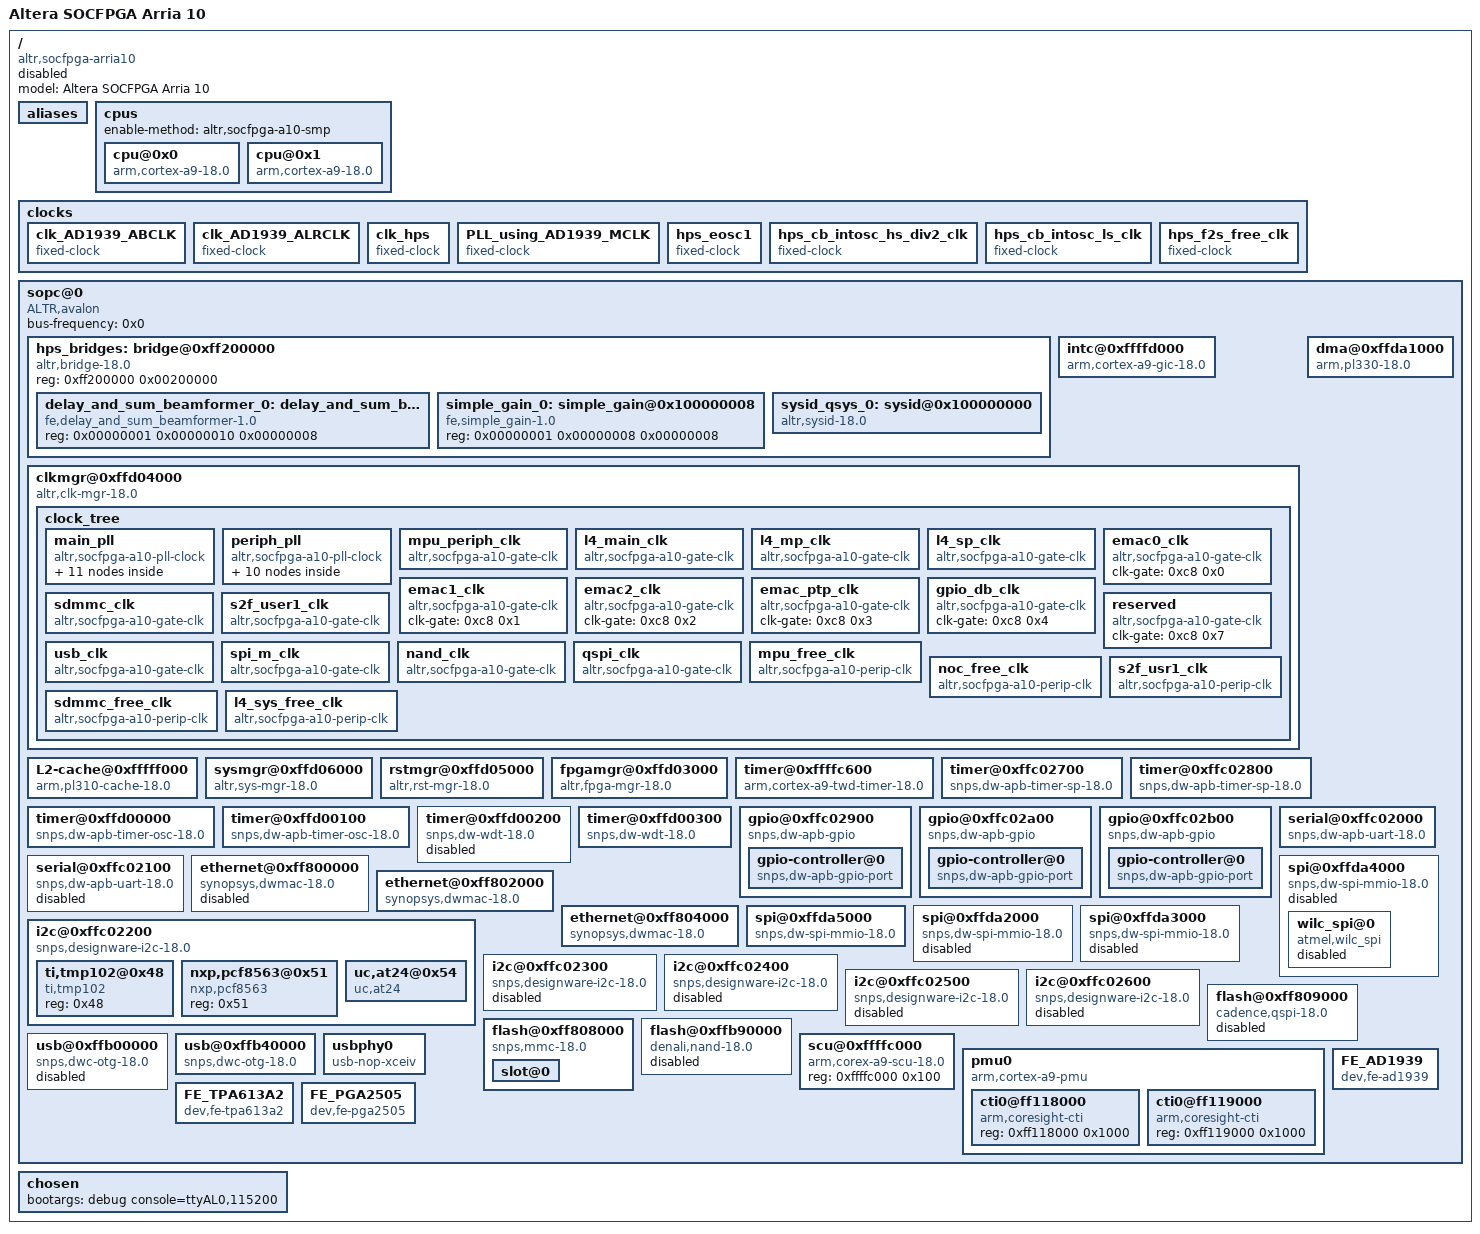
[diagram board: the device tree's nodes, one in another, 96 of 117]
/dts-v1/;

/ {
	model = "Altera SOCFPGA Arria 10";
	compatible = "altr,socfpga-arria10", "altr,socfpga";
	#address-cells = <0x1>;
	#size-cells = <0x1>;
	status = "disabled";

	aliases {
		ethernet0 = "/sopc@0/ethernet@0xff800000";
		ethernet1 = "/sopc@0/ethernet@0xff802000";
		ethernet2 = "/sopc@0/ethernet@0xff804000";
		serial0 = "/sopc@0/serial@0xffc02100";
	};

	cpus {
		#address-cells = <0x1>;
		#size-cells = <0x0>;
		enable-method = "altr,socfpga-a10-smp";

		cpu@0x0 {
			device_type = "cpu";
			compatible = "arm,cortex-a9-18.0", "arm,cortex-a9";
			reg = <0x0>;
			next-level-cache = <0x1>;
		};

		cpu@0x1 {
			device_type = "cpu";
			compatible = "arm,cortex-a9-18.0", "arm,cortex-a9";
			reg = <0x1>;
			next-level-cache = <0x1>;
		};
	};

	clocks {
		#address-cells = <0x1>;
		#size-cells = <0x1>;

		clk_AD1939_ABCLK {
			compatible = "fixed-clock";
			#clock-cells = <0x0>;
			clock-frequency = <0x2faf080>;
			clock-output-names = "clk_AD1939_ABCLK-clk";
		};

		clk_AD1939_ALRCLK {
			compatible = "fixed-clock";
			#clock-cells = <0x0>;
			clock-frequency = <0x2faf080>;
			clock-output-names = "clk_AD1939_ALRCLK-clk";
		};

		clk_hps {
			compatible = "fixed-clock";
			#clock-cells = <0x0>;
			clock-frequency = <0x17d7840>;
			clock-output-names = "clk_hps-clk";
			linux,phandle = <0x2>;
			phandle = <0x2>;
		};

		PLL_using_AD1939_MCLK {
			compatible = "fixed-clock";
			#clock-cells = <0x0>;
			clock-frequency = <0x5dc0000>;
			clock-output-names = "PLL_using_AD1939_MCLK-outclk0";
		};

		hps_eosc1 {
			compatible = "fixed-clock";
			#clock-cells = <0x0>;
			clock-frequency = <0x17d7840>;
			clock-output-names = "hps_eosc1-clk";
			linux,phandle = <0x3>;
			phandle = <0x3>;
		};

		hps_cb_intosc_hs_div2_clk {
			compatible = "fixed-clock";
			#clock-cells = <0x0>;
			clock-frequency = <0x0>;
			clock-output-names = "hps_cb_intosc_hs_div2_clk-clk";
			linux,phandle = <0x4>;
			phandle = <0x4>;
		};

		hps_cb_intosc_ls_clk {
			compatible = "fixed-clock";
			#clock-cells = <0x0>;
			clock-frequency = <0x3938700>;
			clock-output-names = "hps_cb_intosc_ls_clk-clk";
			linux,phandle = <0x5>;
			phandle = <0x5>;
		};

		hps_f2s_free_clk {
			compatible = "fixed-clock";
			#clock-cells = <0x0>;
			clock-frequency = <0xbebc200>;
			clock-output-names = "hps_f2s_free_clk-clk";
			linux,phandle = <0x6>;
			phandle = <0x6>;
		};
	};

	sopc@0 {
		device_type = "soc";
		ranges;
		#address-cells = <0x1>;
		#size-cells = <0x1>;
		compatible = "ALTR,avalon", "simple-bus";
		bus-frequency = <0x0>;

        hps_bridges: bridge@0xff200000 {
                compatible = "altr,bridge-18.0", "simple-bus";
                reg = <0xff200000 0x00200000>;
                #address-cells = <2>;
                #size-cells = <1>;
                ranges = <0x00000001 0x00000010 0xff200010 0x00000008>,
                        <0x00000001 0x00000008 0xff200008 0x00000008>,
                        <0x00000001 0x00000000 0xff200000 0x00000008>;

                delay_and_sum_beamformer_0: delay_and_sum_beamformer@0x100000010 {
                        compatible = "fe,delay_and_sum_beamformer-1.0", "dev,fe-delay_and_sum_beamformer";
                        reg = <0x00000001 0x00000010 0x00000008>;
                }; //end delay_and_sum_beamformer@0x100000010 (delay_and_su m_beamformer_0)

                simple_gain_0: simple_gain@0x100000008 {
                        compatible = "fe,simple_gain-1.0", "dev,fe-simple_gain";
                        reg = <0x00000001 0x00000008 0x00000008>;
                }; //end simple_gain@0x100000008 (simple_gain_0)

                sysid_qsys_0: sysid@0x100000000 {
                        compatible = "altr,sysid-18.0", "altr,sysid-1.0";
                        reg = <0x00000001 0x00000000 0x00000008>;
                        id = <1>;       /* embeddedsw.dts.params.id type NU MBER */
                        timestamp = <1585258689>;       /* embeddedsw.dts.p arams.timestamp type NUMBER */
                }; //end sysid@0x100000000 (sysid_qsys_0)
        }; //end bridge@0xff200000 (hps_bridges)


		intc@0xffffd000 {
			compatible = "arm,cortex-a9-gic-18.0", "arm,cortex-a9-gic";
			reg = <0xffffd000 0x1000 0xffffc100 0x100>;
			reg-names = "axi_slave0", "axi_slave1";
			interrupt-controller;
			#interrupt-cells = <0x3>;
			linux,phandle = <0x17>;
			phandle = <0x17>;
		};

		clkmgr@0xffd04000 {
			compatible = "altr,clk-mgr-18.0", "altr,clk-mgr";
			reg = <0xffd04000 0x1000>;
			clocks = <0x3 0x4 0x5 0x6>;
			clock-names = "eosc1", "cb_intosc_hs_div2_clk", "cb_intosc_ls_clk", "f2s_free_clk";

			clock_tree {
				#size-cells = <0x0>;
				#address-cells = <0x1>;

				main_pll {
					compatible = "altr,socfpga-a10-pll-clock";
					reg = <0x40>;
					clocks = <0x3 0x5 0x6>;
					clock-names = "hps_eosc1", "hps_cb_intosc_ls_clk", "hps_f2s_free_clk";
					#clock-cells = <0x0>;
					#address-cells = <0x1>;
					#size-cells = <0x0>;
					linux,phandle = <0x7>;
					phandle = <0x7>;

					main_mpu_base_clk {
						compatible = "altr,socfpga-a10-perip-clk";
						reg = <0x40>;
						clocks = <0x7>;
						#clock-cells = <0x0>;
						div-reg = <0x140 0x0 0xb>;
						linux,phandle = <0x10>;
						phandle = <0x10>;
					};

					main_noc_base_clk {
						compatible = "altr,socfpga-a10-perip-clk";
						reg = <0x40>;
						clocks = <0x7>;
						#clock-cells = <0x0>;
						div-reg = <0x144 0x0 0xb>;
						linux,phandle = <0x12>;
						phandle = <0x12>;
					};

					main_emaca_clk {
						compatible = "altr,socfpga-a10-perip-clk";
						reg = <0x68>;
						clocks = <0x7>;
						#clock-cells = <0x0>;
					};

					main_emacb_clk {
						compatible = "altr,socfpga-a10-perip-clk";
						reg = <0x6c>;
						clocks = <0x7>;
						#clock-cells = <0x0>;
					};

					main_emac_ptp_clk {
						compatible = "altr,socfpga-a10-perip-clk";
						reg = <0x70>;
						clocks = <0x7>;
						#clock-cells = <0x0>;
					};

					main_gpio_db_clk {
						compatible = "altr,socfpga-a10-perip-clk";
						reg = <0x74>;
						clocks = <0x7>;
						#clock-cells = <0x0>;
					};

					main_sdmmc_clk {
						compatible = "altr,socfpga-a10-perip-clk";
						reg = <0x78>;
						clocks = <0x7>;
						#clock-cells = <0x0>;
						linux,phandle = <0x15>;
						phandle = <0x15>;
					};

					main_s2f_usr0_clk {
						compatible = "altr,socfpga-a10-perip-clk";
						reg = <0x7c>;
						clocks = <0x7>;
						#clock-cells = <0x0>;
					};

					main_s2f_usr1_clk {
						compatible = "altr,socfpga-a10-perip-clk";
						reg = <0x80>;
						clocks = <0x7>;
						#clock-cells = <0x0>;
						linux,phandle = <0x14>;
						phandle = <0x14>;
					};

					main_hmc_pll_ref_clk {
						compatible = "altr,socfpga-a10-perip-clk";
						reg = <0x84>;
						clocks = <0x7>;
						#clock-cells = <0x0>;
					};

					main_periph_ref_clk {
						compatible = "altr,socfpga-a10-perip-clk";
						reg = <0x9c>;
						clocks = <0x7>;
						#clock-cells = <0x0>;
						linux,phandle = <0x8>;
						phandle = <0x8>;
					};
				};

				periph_pll {
					compatible = "altr,socfpga-a10-pll-clock";
					reg = <0xc0>;
					clocks = <0x3 0x5 0x6 0x8>;
					clock-names = "hps_eosc1", "hps_cb_intosc_ls_clk", "hps_f2s_free_clk", "main_periph_ref_clk";
					#clock-cells = <0x0>;
					#address-cells = <0x1>;
					#size-cells = <0x0>;
					linux,phandle = <0x9>;
					phandle = <0x9>;

					peri_mpu_base_clk {
						compatible = "altr,socfpga-a10-perip-clk";
						reg = <0xc0>;
						clocks = <0x9>;
						#clock-cells = <0x0>;
						div-reg = <0x140 0x10 0xb>;
						linux,phandle = <0x11>;
						phandle = <0x11>;
					};

					peri_noc_base_clk {
						compatible = "altr,socfpga-a10-perip-clk";
						reg = <0xc0>;
						clocks = <0x9>;
						#clock-cells = <0x0>;
						div-reg = <0x144 0x10 0xb>;
						linux,phandle = <0x13>;
						phandle = <0x13>;
					};

					peri_emaca_clk {
						compatible = "altr,socfpga-a10-perip-clk";
						reg = <0xe8>;
						clocks = <0x9>;
						#clock-cells = <0x0>;
					};

					peri_emacb_clk {
						compatible = "altr,socfpga-a10-perip-clk";
						reg = <0xec>;
						clocks = <0x9>;
						#clock-cells = <0x0>;
					};

					peri_emac_ptp_clk {
						compatible = "altr,socfpga-a10-perip-clk";
						reg = <0xf0>;
						clocks = <0x9>;
						#clock-cells = <0x0>;
					};

					peri_gpio_db_clk {
						compatible = "altr,socfpga-a10-perip-clk";
						reg = <0xf4>;
						clocks = <0x9>;
						#clock-cells = <0x0>;
					};

					peri_sdmmc_clk {
						compatible = "altr,socfpga-a10-perip-clk";
						reg = <0xf8>;
						clocks = <0x9>;
						#clock-cells = <0x0>;
						linux,phandle = <0x16>;
						phandle = <0x16>;
					};

					peri_s2f_usr0_clk {
						compatible = "altr,socfpga-a10-perip-clk";
						reg = <0xfc>;
						clocks = <0x9>;
						#clock-cells = <0x0>;
					};

					peri_s2f_usr1_clk {
						compatible = "altr,socfpga-a10-perip-clk";
						reg = <0x100>;
						clocks = <0x9>;
						#clock-cells = <0x0>;
						linux,phandle = <0xd>;
						phandle = <0xd>;
					};

					peri_hmc_pll_ref_clk {
						compatible = "altr,socfpga-a10-perip-clk";
						reg = <0x104>;
						clocks = <0x9>;
						#clock-cells = <0x0>;
					};
				};

				mpu_periph_clk {
					compatible = "altr,socfpga-a10-gate-clk";
					clocks = <0xa>;
					#clock-cells = <0x0>;
					clk-gate = <0x48 0x0>;
					fixed-divider = <0x4>;
					linux,phandle = <0x18>;
					phandle = <0x18>;
				};

				l4_main_clk {
					compatible = "altr,socfpga-a10-gate-clk";
					clocks = <0xb>;
					#clock-cells = <0x0>;
					clk-gate = <0x48 0x1>;
					div-reg = <0xa8 0x0 0x2>;
					linux,phandle = <0xf>;
					phandle = <0xf>;
				};

				l4_mp_clk {
					compatible = "altr,socfpga-a10-gate-clk";
					clocks = <0xb>;
					#clock-cells = <0x0>;
					clk-gate = <0x48 0x2>;
					div-reg = <0xa8 0x8 0x2>;
					linux,phandle = <0xe>;
					phandle = <0xe>;
				};

				l4_sp_clk {
					compatible = "altr,socfpga-a10-gate-clk";
					clocks = <0xb>;
					#clock-cells = <0x0>;
					clk-gate = <0x48 0x3>;
					div-reg = <0xa8 0x10 0x2>;
					linux,phandle = <0x19>;
					phandle = <0x19>;
				};

				emac0_clk {
					compatible = "altr,socfpga-a10-gate-clk";
					#clock-cells = <0x0>;
					clk-gate = <0xc8 0x0>;
				};

				emac1_clk {
					compatible = "altr,socfpga-a10-gate-clk";
					#clock-cells = <0x0>;
					clk-gate = <0xc8 0x1>;
				};

				emac2_clk {
					compatible = "altr,socfpga-a10-gate-clk";
					#clock-cells = <0x0>;
					clk-gate = <0xc8 0x2>;
				};

				emac_ptp_clk {
					compatible = "altr,socfpga-a10-gate-clk";
					#clock-cells = <0x0>;
					clk-gate = <0xc8 0x3>;
				};

				gpio_db_clk {
					compatible = "altr,socfpga-a10-gate-clk";
					#clock-cells = <0x0>;
					clk-gate = <0xc8 0x4>;
				};

				sdmmc_clk {
					compatible = "altr,socfpga-a10-gate-clk";
					clocks = <0xc>;
					#clock-cells = <0x0>;
					clk-gate = <0xc8 0x5>;
					clk-phase = <0x0 0x87>;
					linux,phandle = <0x1f>;
					phandle = <0x1f>;
				};

				s2f_user1_clk {
					compatible = "altr,socfpga-a10-gate-clk";
					clocks = <0xd>;
					#clock-cells = <0x0>;
					clk-gate = <0xc8 0x6>;
				};

				reserved {
					compatible = "altr,socfpga-a10-gate-clk";
					#clock-cells = <0x0>;
					clk-gate = <0xc8 0x7>;
				};

				usb_clk {
					compatible = "altr,socfpga-a10-gate-clk";
					clocks = <0xe>;
					#clock-cells = <0x0>;
					clk-gate = <0xc8 0x8>;
					linux,phandle = <0x20>;
					phandle = <0x20>;
				};

				spi_m_clk {
					compatible = "altr,socfpga-a10-gate-clk";
					clocks = <0xf>;
					#clock-cells = <0x0>;
					clk-gate = <0xc8 0x9>;
					linux,phandle = <0x1d>;
					phandle = <0x1d>;
				};

				nand_clk {
					compatible = "altr,socfpga-a10-gate-clk";
					clocks = <0xe>;
					#clock-cells = <0x0>;
					clk-gate = <0xc8 0xa>;
				};

				qspi_clk {
					compatible = "altr,socfpga-a10-gate-clk";
					clocks = <0xf>;
					#clock-cells = <0x0>;
					clk-gate = <0xc8 0xb>;
					linux,phandle = <0x1e>;
					phandle = <0x1e>;
				};

				mpu_free_clk {
					compatible = "altr,socfpga-a10-perip-clk";
					clocks = <0x10 0x11 0x3 0x4 0x6>;
					clock-names = "main_mpu_base_clk", "peri_mpu_base_clk", "hps_eosc1", "hps_cb_intosc_hs_div2_clk", "hps_f2s_free_clk";
					#clock-cells = <0x0>;
					reg = <0x60>;
					linux,phandle = <0xa>;
					phandle = <0xa>;
				};

				noc_free_clk {
					compatible = "altr,socfpga-a10-perip-clk";
					clocks = <0x12 0x13 0x3 0x4 0x6>;
					clock-names = "main_noc_base_clk", "peri_noc_base_clk", "hps_eosc1", "hps_cb_intosc_hs_div2_clk", "hps_f2s_free_clk";
					#clock-cells = <0x0>;
					reg = <0x64>;
					linux,phandle = <0xb>;
					phandle = <0xb>;
				};

				s2f_usr1_clk {
					compatible = "altr,socfpga-a10-perip-clk";
					clocks = <0x14 0xd 0x3 0x4 0x6>;
					clock-names = "main_s2f_usr1_clk", "peri_s2f_usr1_clk", "hps_eosc1", "hps_cb_intosc_hs_div2_clk", "hps_f2s_free_clk";
					#clock-cells = <0x0>;
					reg = <0x104>;
				};

				sdmmc_free_clk {
					compatible = "altr,socfpga-a10-perip-clk";
					clocks = <0x15 0x16 0x3 0x4 0x6>;
					clock-names = "main_sdmmc_clk", "peri_sdmmc_clk", "hps_eosc1", "hps_cb_intosc_hs_div2_clk", "hps_f2s_free_clk";
					#clock-cells = <0x0>;
					reg = <0xf8>;
					fixed-divider = <0x4>;
					linux,phandle = <0xc>;
					phandle = <0xc>;
				};

				l4_sys_free_clk {
					compatible = "altr,socfpga-a10-perip-clk";
					clocks = <0xb>;
					#clock-cells = <0x0>;
					fixed-divider = <0x4>;
					linux,phandle = <0x1a>;
					phandle = <0x1a>;
				};
			};
		};

		L2-cache@0xfffff000 {
			compatible = "arm,pl310-cache-18.0", "arm,pl310-cache";
			reg = <0xfffff000 0x1000>;
			interrupt-parent = <0x17>;
			interrupts = <0x0 0x12 0x4>;
			cache-level = <0x2>;
			cache-unified;
			arm,tag-latency = <0x1 0x1 0x1>;
			arm,data-latency = <0x2 0x1 0x1>;
			linux,phandle = <0x1>;
			phandle = <0x1>;
		};

		dma@0xffda1000 {
			compatible = "arm,pl330-18.0", "arm,pl330", "arm,primecell";
			reg = <0xffda1000 0x1000>;
			interrupt-parent = <0x17>;
			interrupts = <0x0 0x53 0x4>;
			clocks = <0xf>;
			#dma-cells = <0x1>;
			#dma-channels = <0x8>;
			#dma-requests = <0x20>;
			clock-names = "apb_pclk";
			copy-align = <0x3>;
			nr-irqs = <0x9>;
			nr-valid-peri = <0x9>;
		};

		sysmgr@0xffd06000 {
			compatible = "altr,sys-mgr-18.0", "altr,sys-mgr", "syscon";
			reg = <0xffd06000 0x400>;
			cpu1-start-addr = <0xffd06230>;
			linux,phandle = <0x1c>;
			phandle = <0x1c>;
		};

		rstmgr@0xffd05000 {
			compatible = "altr,rst-mgr-18.0", "altr,rst-mgr", "syscon";
			reg = <0xffd05000 0x100>;
			#reset-cells = <0x1>;
			altr,modrst-offset = <0x20>;
			linux,phandle = <0x1b>;
			phandle = <0x1b>;
		};

		fpgamgr@0xffd03000 {
			compatible = "altr,fpga-mgr-18.0", "altr,socfpga-a10-fpga-mgr";
			reg = <0xffd03000 0x1000 0xffcfe400 0x100>;
			reg-names = "axi_slave0", "axi_slave1";
			interrupt-parent = <0x17>;
			interrupts = <0x0 0x7b 0x4>;
			transport = "mmio";
			clocks = <0xe>;
		};

		timer@0xffffc600 {
			compatible = "arm,cortex-a9-twd-timer-18.0", "arm,cortex-a9-twd-timer";
			reg = <0xffffc600 0x100>;
			interrupt-parent = <0x17>;
			interrupts = <0x1 0xd 0xf04>;
			clocks = <0x18>;
		};

		timer@0xffc02700 {
			compatible = "snps,dw-apb-timer-sp-18.0", "snps,dw-apb-timer-sp";
			reg = <0xffc02700 0x100>;
			interrupt-parent = <0x17>;
			interrupts = <0x0 0x73 0x4>;
			clocks = <0x19>;
			clock-names = "timer";
		};

		timer@0xffc02800 {
			compatible = "snps,dw-apb-timer-sp-18.0", "snps,dw-apb-timer-sp";
			reg = <0xffc02800 0x100>;
			interrupt-parent = <0x17>;
			interrupts = <0x0 0x74 0x4>;
			clocks = <0x19>;
			clock-names = "timer";
		};

		timer@0xffd00000 {
			compatible = "snps,dw-apb-timer-osc-18.0", "snps,dw-apb-timer-osc";
			reg = <0xffd00000 0x100>;
			interrupt-parent = <0x17>;
			interrupts = <0x0 0x75 0x4>;
			clocks = <0x1a>;
			clock-names = "timer";
		};

		timer@0xffd00100 {
			compatible = "snps,dw-apb-timer-osc-18.0", "snps,dw-apb-timer-osc";
			reg = <0xffd00100 0x100>;
			interrupt-parent = <0x17>;
			interrupts = <0x0 0x76 0x4>;
			clocks = <0x1a>;
			clock-names = "timer";
		};

		timer@0xffd00200 {
			compatible = "snps,dw-wdt-18.0", "snps,dw-wdt";
			reg = <0xffd00200 0x100>;
			interrupt-parent = <0x17>;
			interrupts = <0x0 0x77 0x4>;
			clocks = <0x1a>;
			clock-names = "timer";
			status = "disabled";
		};

		timer@0xffd00300 {
			compatible = "snps,dw-wdt-18.0", "snps,dw-wdt";
			reg = <0xffd00300 0x100>;
			interrupt-parent = <0x17>;
			interrupts = <0x0 0x78 0x4>;
			clocks = <0x1a>;
			clock-names = "timer";
		};

		gpio@0xffc02900 {
			compatible = "snps,dw-apb-gpio", "snps,dw-gpio-18.0", "snps,dw-gpio";
			reg = <0xffc02900 0x100>;
			interrupt-parent = <0x17>;
			interrupts = <0x0 0x70 0x4>;
			clocks = <0xe>;
			#gpio-cells = <0x2>;
			gpio-controller;
			#address-cells = <0x1>;
			#size-cells = <0x0>;

			gpio-controller@0 {
				compatible = "snps,dw-apb-gpio-port";
				gpio-controller;
				#gpio-cells = <0x2>;
				snps,nr-gpios = <0x18>;
				reg = <0x0>;
				interrupt-controller;
				#interrupt-cells = <0x2>;
				interrupts = <0x0 0x70 0x4>;
				interrupt-parent = <0x17>;
			};
		};

		gpio@0xffc02a00 {
			compatible = "snps,dw-apb-gpio", "snps,dw-gpio-18.0", "snps,dw-gpio";
			reg = <0xffc02a00 0x100>;
			interrupt-parent = <0x17>;
			interrupts = <0x0 0x71 0x4>;
			clocks = <0xe>;
			#gpio-cells = <0x2>;
			gpio-controller;
			#address-cells = <0x1>;
			#size-cells = <0x0>;

			gpio-controller@0 {
				compatible = "snps,dw-apb-gpio-port";
				gpio-controller;
				#gpio-cells = <0x2>;
				snps,nr-gpios = <0x18>;
				reg = <0x0>;
				interrupt-controller;
				#interrupt-cells = <0x2>;
				interrupts = <0x0 0x71 0x4>;
				interrupt-parent = <0x17>;
			};
		};

		gpio@0xffc02b00 {
			compatible = "snps,dw-apb-gpio", "snps,dw-gpio-18.0", "snps,dw-gpio";
			reg = <0xffc02b00 0x100>;
			interrupt-parent = <0x17>;
			interrupts = <0x0 0x72 0x4>;
			clocks = <0xe>;
			#gpio-cells = <0x2>;
			gpio-controller;
			#address-cells = <0x1>;
			#size-cells = <0x0>;

			gpio-controller@0 {
				compatible = "snps,dw-apb-gpio-port";
				gpio-controller;
				#gpio-cells = <0x2>;
				snps,nr-gpios = <0xe>;
				reg = <0x0>;
				interrupt-controller;
				#interrupt-cells = <0x2>;
				interrupts = <0x0 0x72 0x4>;
				interrupt-parent = <0x17>;
			};
		};

		serial@0xffc02000 {
			compatible = "snps,dw-apb-uart-18.0", "snps,dw-apb-uart";
			reg = <0xffc02000 0x100>;
			interrupt-parent = <0x17>;
			interrupts = <0x0 0x6e 0x4>;
			clocks = <0x19>;
			reg-io-width = <0x4>;
			reg-shift = <0x2>;
			status = "okay";
		};

		serial@0xffc02100 {
			compatible = "snps,dw-apb-uart-18.0", "snps,dw-apb-uart";
			reg = <0xffc02100 0x100>;
			interrupt-parent = <0x17>;
			interrupts = <0x0 0x6f 0x4>;
			clocks = <0x19>;
			reg-io-width = <0x4>;
			reg-shift = <0x2>;
			status = "disabled";
		};

		ethernet@0xff800000 {
			compatible = "synopsys,dwmac-18.0", "altr,socfpga-stmmac", "snps,dwmac-3.72a", "snps,dwmac";
			reg = <0xff800000 0x2000>;
			interrupt-parent = <0x17>;
			interrupts = <0x0 0x5c 0x4>;
			clocks = <0xe>;
			clock-names = "stmmaceth";
			interrupt-names = "macirq";
			rx-fifo-depth = <0x4000>;
			snps,multicast-filter-bins = <0x100>;
			snps,perfect-filter-entries = <0x80>;
			status = "disabled";
			tx-fifo-depth = <0x1000>;
			address-bits = <0x30>;
			max-frame-size = <0x5ee>;
			local-mac-address = [00 00 00 00 00 00];
			resets = <0x1b 0x20>;
			reset-names = "stmmaceth";
			altr,sysmgr-syscon = <0x1c 0x44 0x0>;
		};

		ethernet@0xff802000 {
			compatible = "synopsys,dwmac-18.0", "altr,socfpga-stmmac", "snps,dwmac-3.72a", "snps,dwmac";
			reg = <0xff802000 0x2000>;
			interrupt-parent = <0x17>;
			interrupts = <0x0 0x5d 0x4>;
			clocks = <0xe>;
			clock-names = "stmmaceth";
			interrupt-names = "macirq";
			rx-fifo-depth = <0x4000>;
			snps,multicast-filter-bins = <0x100>;
			snps,perfect-filter-entries = <0x80>;
			status = "okay";
			tx-fifo-depth = <0x1000>;
			address-bits = <0x30>;
			max-frame-size = <0xed8>;
			local-mac-address = [00 00 00 00 00 00];
			resets = <0x1b 0x21>;
			reset-names = "stmmaceth";
			altr,sysmgr-syscon = <0x1c 0x48 0x0>;
			phy-mode = "rgmii";
			phy-addr = <0xffffffff>;
			txd0-skew-ps = <0x0>;
			txd1-skew-ps = <0x0>;
			txd2-skew-ps = <0x0>;
			txd3-skew-ps = <0x0>;
			rxd0-skew-ps = <0x1a4>;
			rxd1-skew-ps = <0x1a4>;
			rxd2-skew-ps = <0x1a4>;
			rxd3-skew-ps = <0x1a4>;
			txen-skew-ps = <0x0>;
			txc-skew-ps = <0x744>;
			rxdv-skew-ps = <0x1a4>;
			rxc-skew-ps = <0x690>;
		};

		ethernet@0xff804000 {
			compatible = "synopsys,dwmac-18.0", "altr,socfpga-stmmac", "snps,dwmac-3.72a", "snps,dwmac";
			reg = <0xff804000 0x2000>;
			interrupt-parent = <0x17>;
			interrupts = <0x0 0x5e 0x4>;
			clocks = <0xe>;
			clock-names = "stmmaceth";
			interrupt-names = "macirq";
			rx-fifo-depth = <0x4000>;
			snps,multicast-filter-bins = <0x100>;
			snps,perfect-filter-entries = <0x80>;
			status = "okay";
			tx-fifo-depth = <0x1000>;
			address-bits = <0x30>;
			max-frame-size = <0xed8>;
			local-mac-address = [00 00 00 00 00 00];
			resets = <0x1b 0x22>;
			reset-names = "stmmaceth";
			altr,sysmgr-syscon = <0x1c 0x4c 0x0>;
			phy-mode = "rgmii";
			phy-addr = <0xffffffff>;
			txd0-skew-ps = <0x0>;
			txd1-skew-ps = <0x0>;
			txd2-skew-ps = <0x0>;
			txd3-skew-ps = <0x0>;
			rxd0-skew-ps = <0x1a4>;
			rxd1-skew-ps = <0x1a4>;
			rxd2-skew-ps = <0x1a4>;
			rxd3-skew-ps = <0x1a4>;
			txen-skew-ps = <0x0>;
			txc-skew-ps = <0x744>;
			rxdv-skew-ps = <0x1a4>;
			rxc-skew-ps = <0x690>;
		};

		spi@0xffda4000 {
			compatible = "snps,dw-spi-mmio-18.0", "snps,dw-spi-mmio", "snps,dw-apb-ssi";
			reg = <0xffda4000 0x100>;
			interrupt-parent = <0x17>;
			interrupts = <0x0 0x67 0x4>;
			clocks = <0x1d>;
			#address-cells = <0x1>;
			#size-cells = <0x0>;
			bus-num = <0x0>;
			num-chipselect = <0x4>;
			status = "disabled";

			wilc_spi@0 {
				compatible = "atmel,wilc_spi";
				spi-max-frequency = <0x5b8d80>;
				reg = <0x0>;
				status = "disabled";
			};
		};

		spi@0xffda5000 {
			compatible = "snps,dw-spi-mmio-18.0", "snps,dw-spi-mmio", "snps,dw-apb-ssi";
			reg = <0xffda5000 0x100>;
			interrupt-parent = <0x17>;
			interrupts = <0x0 0x66 0x4>;
			clocks = <0x1d>;
			#address-cells = <0x1>;
			#size-cells = <0x0>;
			bus-num = <0x0>;
			num-chipselect = <0x4>;
			status = "okay";
			tx-dma-channel = <0x1d 0x10>;
			rx-dma-channel = <0x1d 0x11>;
			32bit_access;
		};

		spi@0xffda2000 {
			compatible = "snps,dw-spi-mmio-18.0", "snps,dw-spi-mmio", "snps,dw-apb-ssi";
			reg = <0xffda2000 0x100>;
			interrupt-parent = <0x17>;
			interrupts = <0x0 0x65 0x4>;
			clocks = <0xe>;
			#address-cells = <0x1>;
			#size-cells = <0x0>;
			bus-num = <0x0>;
			num-chipselect = <0x4>;
			status = "disabled";
		};

		spi@0xffda3000 {
			compatible = "snps,dw-spi-mmio-18.0", "snps,dw-spi-mmio", "snps,dw-apb-ssi";
			reg = <0xffda3000 0x100>;
			interrupt-parent = <0x17>;
			interrupts = <0x0 0x66 0x4>;
			clocks = <0xe>;
			#address-cells = <0x1>;
			#size-cells = <0x0>;
			bus-num = <0x0>;
			num-chipselect = <0x4>;
			status = "disabled";
		};

		i2c@0xffc02200 {
			compatible = "snps,designware-i2c-18.0", "snps,designware-i2c";
			reg = <0xffc02200 0x100>;
			interrupt-parent = <0x17>;
			interrupts = <0x0 0x69 0x4>;
			clocks = <0x19>;
			emptyfifo_hold_master = <0x1>;
			status = "okay";
			#address-cells = <0x1>;
			#size-cells = <0x0>;
			speed-mode = <0x0>;
			clock-frequency = <0x186a0>;
			i2c-sda-falling-time-ns = <0x1770>;
			i2c-scl-falling-time-ns = <0x1770>;

			ti,tmp102@0x48 {
				compatible = "ti,tmp102";
				reg = <0x48>;
			};

			nxp,pcf8563@0x51 {
				compatible = "nxp,pcf8563";
				reg = <0x51>;
			};

			uc,at24@0x54 {
				compatible = "uc,at24";
				reg = <0x54>;
				bytelen = <0x100>;
				pagesize = <0x10>;
			};
		};

		i2c@0xffc02300 {
			compatible = "snps,designware-i2c-18.0", "snps,designware-i2c";
			reg = <0xffc02300 0x100>;
			interrupt-parent = <0x17>;
			interrupts = <0x0 0x6a 0x4>;
			clocks = <0x19>;
			emptyfifo_hold_master = <0x1>;
			status = "disabled";
		};

		i2c@0xffc02400 {
			compatible = "snps,designware-i2c-18.0", "snps,designware-i2c";
			reg = <0xffc02400 0x100>;
			interrupt-parent = <0x17>;
			interrupts = <0x0 0x6b 0x4>;
			clocks = <0x19>;
			emptyfifo_hold_master = <0x1>;
			status = "disabled";
		};

		i2c@0xffc02500 {
			compatible = "snps,designware-i2c-18.0", "snps,designware-i2c";
			reg = <0xffc02500 0x100>;
			interrupt-parent = <0x17>;
			interrupts = <0x0 0x6c 0x4>;
			clocks = <0x19>;
			emptyfifo_hold_master = <0x1>;
			status = "disabled";
		};

		i2c@0xffc02600 {
			compatible = "snps,designware-i2c-18.0", "snps,designware-i2c";
			reg = <0xffc02600 0x100>;
			interrupt-parent = <0x17>;
			interrupts = <0x0 0x6d 0x4>;
			clocks = <0x19>;
			emptyfifo_hold_master = <0x1>;
			status = "disabled";
		};

		flash@0xff809000 {
			compatible = "cadence,qspi-18.0", "cadence,qspi", "cdns,qspi-nor";
			reg = <0xff809000 0x100 0xffa00000 0x100>;
			reg-names = "axi_slave0", "axi_slave1";
			interrupt-parent = <0x17>;
			interrupts = <0x0 0x64 0x4>;
			clocks = <0x1e>;
			bus-num = <0x2>;
			fifo-depth = <0x80>;
			num-chipselect = <0x4>;
			status = "disabled";
			bank-width = <0x2>;
			device-width = <0x1>;
		};

		flash@0xff808000 {
			compatible = "snps,mmc-18.0", "altr,socfpga-dw-mshc";
			reg = <0xff808000 0x1000>;
			interrupt-parent = <0x17>;
			interrupts = <0x0 0x62 0x4>;
			clocks = <0xe 0x1f>;
			clock-names = "biu", "ciu";
			fifo-depth = <0x400>;
			num-slots = <0x1>;
			status = "okay";
			bank-width = <0x2>;
			device-width = <0x1>;
			supports-highspeed;
			broken-cd;
			cap-sd-highspeed;
			altr,dw-mshc-ciu-div = <0x3>;
			altr,dw-mshc-sdr-timing = <0x0 0x3>;
			pwr-en = <0x0>;
			#address-cells = <0x1>;
			#size-cells = <0x0>;
			bus-width = <0x8>;

			slot@0 {
				reg = <0x0>;
				bus-width = <0x8>;
			};
		};

		flash@0xffb90000 {
			compatible = "denali,nand-18.0", "denali,denali-nand-dt";
			reg = <0xffb90000 0x10000 0xffb80000 0x10000>;
			reg-names = "nand_data", "denali_reg";
			interrupt-parent = <0x17>;
			interrupts = <0x0 0x63 0x4>;
			clocks = <0xe>;
			#address-cells = <0x1>;
			#size-cells = <0x1>;
			status = "disabled";
			bank-width = <0x2>;
			device-width = <0x1>;
		};

		usb@0xffb00000 {
			compatible = "snps,dwc-otg-18.0", "snps,dwc-otg", "snps,dwc2";
			reg = <0xffb00000 0x40000>;
			interrupt-parent = <0x17>;
			interrupts = <0x0 0x5f 0x4>;
			clocks = <0x20>;
			clock-names = "otg";
			dev-nperio-tx-fifo-size = <0x1000>;
			dev-perio-tx-fifo-size = "<512 512 512 512 512 512 512 512 512 512 512 512 512 512 512>";
			dev-rx-fifo-size = <0x200>;
			dev-tx-fifo-size = "<512 512 512 512 512 512 512 512 512 512 512 512 512 512 512>";
			dma-mask = <0xfffffff>;
			enable-dynamic-fifo = <0x1>;
			host-nperio-tx-fifo-size = <0xa00>;
			host-perio-tx-fifo-size = <0xa00>;
			host-rx-fifo-size = <0xa00>;
			phy-names = "usb2-phy";
			status = "disabled";
			ulpi-ddr = <0x0>;
			voltage-switch = <0x0>;
			phys = <0x21>;
		};

		usb@0xffb40000 {
			compatible = "snps,dwc-otg-18.0", "snps,dwc-otg", "snps,dwc2";
			reg = <0xffb40000 0x40000>;
			interrupt-parent = <0x17>;
			interrupts = <0x0 0x60 0x4>;
			clocks = <0x20>;
			clock-names = "otg";
			dev-nperio-tx-fifo-size = <0x1000>;
			dev-perio-tx-fifo-size = "<512 512 512 512 512 512 512 512 512 512 512 512 512 512 512>";
			dev-rx-fifo-size = <0x200>;
			dev-tx-fifo-size = "<512 512 512 512 512 512 512 512 512 512 512 512 512 512 512>";
			dma-mask = <0xfffffff>;
			enable-dynamic-fifo = <0x1>;
			host-nperio-tx-fifo-size = <0xa00>;
			host-perio-tx-fifo-size = <0xa00>;
			host-rx-fifo-size = <0xa00>;
			phy-names = "usb2-phy";
			status = "okay";
			ulpi-ddr = <0x0>;
			voltage-switch = <0x0>;
		};

		scu@0xffffc000 {
			compatible = "arm,corex-a9-scu-18.0", "arm,cortex-a9-scu";
			reg = <0xffffc000 0x100>;
		};

		pmu0 {
			#address-cells = <0x1>;
			#size-cells = <0x1>;
			compatible = "arm,cortex-a9-pmu";
			interrupt-parent = <0x17>;
			interrupts = <0x0 0xb0 0x4 0x0 0xb1 0x4>;
			ranges;

			cti0@ff118000 {
				compatible = "arm,coresight-cti";
				reg = <0xff118000 0x1000>;
			};

			cti0@ff119000 {
				compatible = "arm,coresight-cti";
				reg = <0xff119000 0x1000>;
			};
		};

		usbphy0 {
			#phy-cells = <0x0>;
			compatible = "usb-nop-xceiv";
			status = "okay";
			linux,phandle = <0x21>;
			phandle = <0x21>;
		};

		FE_AD1939 {
			compatible = "dev,fe-ad1939";
		};

		FE_TPA613A2 {
			compatible = "dev,fe-tpa613a2";
		};

		FE_PGA2505 {
			compatible = "dev,fe-pga2505";
		};
	};

	chosen {
		bootargs = "debug console=ttyAL0,115200";
	};
};
